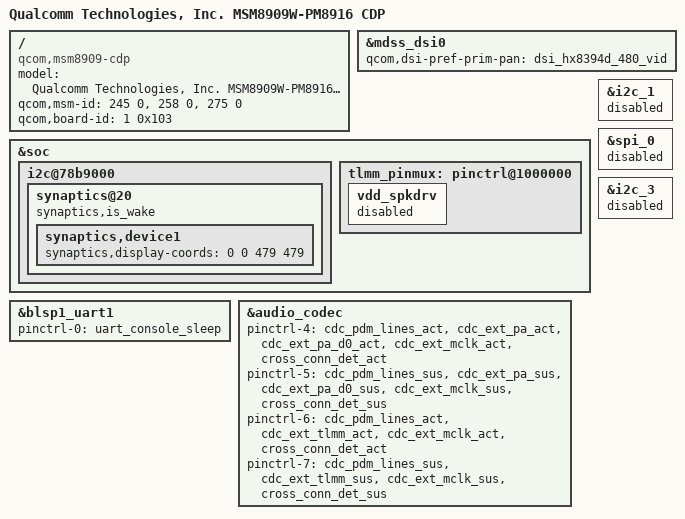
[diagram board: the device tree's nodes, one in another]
/*
 * Copyright (c) 2015, The Linux Foundation. All rights reserved.
 *
 * This program is free software; you can redistribute it and/or modify
 * it under the terms of the GNU General Public License version 2 and
 * only version 2 as published by the Free Software Foundation.
 *
 * This program is distributed in the hope that it will be useful,
 * but WITHOUT ANY WARRANTY; without even the implied warranty of
 * MERCHANTABILITY or FITNESS FOR A PARTICULAR PURPOSE.  See the
 * GNU General Public License for more details.
 */

/dts-v1/;

#include "msm8909-cdp.dtsi"
#include "msm8909-gpu-w.dtsi"
#include "msm8909-pm8916.dtsi"
#include "msm8909-pm8916-cdp.dtsi"

/ {
	model = "Qualcomm Technologies, Inc. MSM8909W-PM8916 CDP";
	compatible = "qcom,msm8909-cdp", "qcom,msm8909", "qcom,cdp";
	qcom,msm-id =   <245 0>,
			<258 0>,
			<275 0>;
	qcom,board-id= <1 0x103>;
};

&mdss_dsi0 {
	qcom,dsi-pref-prim-pan = <&dsi_hx8394d_480_vid>;
};

&soc {
	i2c@78b9000 { /* BLSP1 QUP5 */
		synaptics@20 {
			/delete-property/ synaptics,power-down;
			/delete-property/ synaptics,disable-gpios;
			synaptics,is_wake;
			synaptics,device1 {
				synaptics,display-coords = <0 0 479 479>;
			};
		};
	};
};

&i2c_1 {
	status = "disabled";
};

&spi_0 {
	status = "disabled";
};

&i2c_3 {
	status = "disabled";
};

&blsp1_uart1 {
	status = "ok";
	pinctrl-names = "default";
	pinctrl-0 = <&uart_console_sleep>;
};

&audio_codec {
	pinctrl-4 =     <&cdc_pdm_lines_act &cdc_ext_pa_act
			&cdc_ext_pa_d0_act &cdc_ext_mclk_act
			&cross_conn_det_act>;
	pinctrl-5 =     <&cdc_pdm_lines_sus &cdc_ext_pa_sus
			&cdc_ext_pa_d0_sus &cdc_ext_mclk_sus
			&cross_conn_det_sus>;
	pinctrl-6 =     <&cdc_pdm_lines_act &cdc_ext_tlmm_act
			&cdc_ext_mclk_act &cross_conn_det_act>;
	pinctrl-7 =     <&cdc_pdm_lines_sus &cdc_ext_tlmm_sus
			&cdc_ext_mclk_sus &cross_conn_det_sus>;
};

&soc {
	tlmm_pinmux: pinctrl@1000000 {
		vdd_spkdrv {
			status = "disabled";
		};
	};
};
